AUTOSAR XML (schema 4-2-2)
package /AUTOSAR/Components
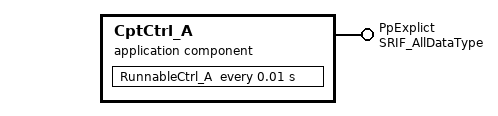
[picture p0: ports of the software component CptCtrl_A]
  application sw component type CptCtrl_A
    provide port PpExplict: provided-interface=SRIF_AllDataType
    behavior IbCtrl_A
      timing event timingEvent_10: start-on-event=RunnableCtrl_A, period=0.01
      runnable RunnableCtrl_A: symbol=AppRunnableCtrl
        data-send-points:
          access DataSendPointsPrimitive: accessed-variable=PpExplict.dataElementPrimitive
          access dataSendPointsArray: accessed-variable=PpExplict.dataElementArray
          access dataSendPointsStruct: accessed-variable=PpExplict.dataElementStruct
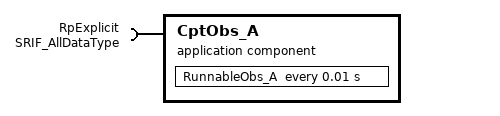
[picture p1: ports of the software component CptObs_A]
  application sw component type CptObs_A
    require port RpExplicit: required-interface=SRIF_AllDataType
      required-com-specs:
        data-element=dataElementPrimitive, external-replacement=dataElementPrimitive, init-value=0
        data-element=dataElementStruct, init-value=fields=[0, 1, 2]
        data-element=dataElementArray, init-value=[0]
    behavior IbObs_A
      timing event timingEvent_10: start-on-event=RunnableObs_A, period=0.01
      runnable RunnableObs_A: symbol=AppRunnable_Obs
        data-receive-point-by-arguments:
          access DataReceiveByArgPrimitive: accessed-variable=RpExplicit.dataElementPrimitive
          access DataReceiveByArgArray: accessed-variable=RpExplicit.dataElementArray
          access DataReceiveByArgStruct: accessed-variable=RpExplicit.dataElementStruct
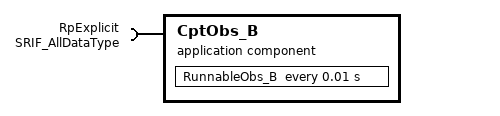
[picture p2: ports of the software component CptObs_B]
  application sw component type CptObs_B
    require port RpExplicit: required-interface=SRIF_AllDataType
      required-com-specs:
        data-element=dataElementPrimitive, init-value=0
        data-element=dataElementStruct, init-value=fields=[0, 1, 2]
        data-element=dataElementArray, init-value=[0]
    behavior IbObs_B
      timing event timingEvent_10: start-on-event=RunnableObs_B, period=0.01
      runnable RunnableObs_B: symbol=AppRunnableObs_1B
        data-receive-point-by-arguments:
          access DataReceiveByArgPrimitive: accessed-variable=RpExplicit.dataElementPrimitive
          access DataReceiveByArgArray: accessed-variable=RpExplicit.dataElementArray
          access DataReceiveByArgStruct: accessed-variable=RpExplicit.dataElementStruct
